# IND83215A register map
Series: Verne; File version: A0
CPU: CM0 r0p1, selectable endian, no MPU, no FPU, 4 interrupt priority bits
Registers are 32-bit, read-write, no defined reset value unless marked. A register's access mark holds for its fields unless they carry their own. Offsets are from the block's base; [hi:lo] are bit positions.

## CRGA — Clock & Reset Generator
Base 0x50000000; register names take the prefix CRGA_
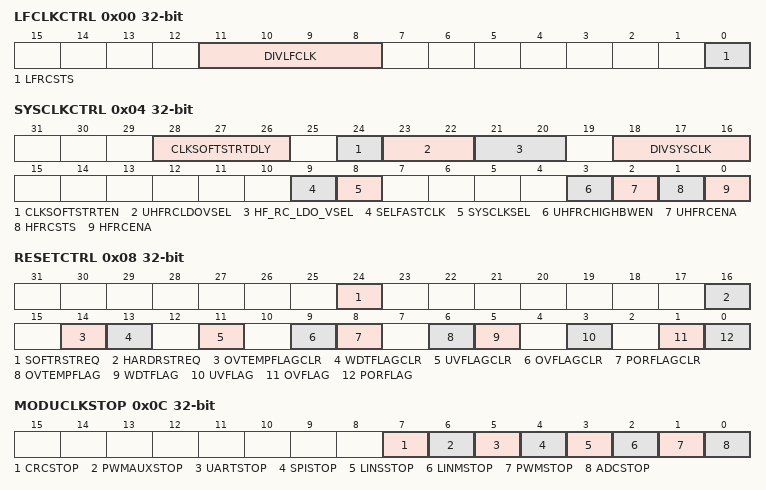
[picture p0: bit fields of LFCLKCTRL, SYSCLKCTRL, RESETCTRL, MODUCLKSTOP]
0x00 LFCLKCTRL — Low frequency clock control
  [11:8] DIVLFCLK — Low Frequency Clock div select. Select the divider ratio on the low Frequency clock when using slow oscillator. Divider ratio is (DIV_LFCLK + 1)
  [0] LFRCSTS ro — Slow oscillator status. Will be high when the Low Frequency oscillator is selected
0x04 SYSCLKCTRL — System clock control
  [28:26] CLKSOFTSTRTDLY — Define the duration of cycles of each divider ratio when soft starting. NOTE: Fast clock selected by SEL_FASTCLK must have been enabled (HF_RC_ENA or UHF_RC_ENA) when change this field. 0x0: 2 divided clock 0x1: 4 divided clock 0x2: 8 divided clock 0x3: 16 divided clock 0x4: 32 divided clock 0x5: 64 divided clock 0x6: 128 divided clock 0x7: 256 divided clock
  [24] CLKSOFTSTRTEN — Enable Clock Soft Starter when change SYSCLKSEL from 0 to 1 for switching to fast clock. When enabled, soft starter will start the clock divider with the maximum divider ratio. And decrease divider ratio by one after staying for predefined number of cycles defined in register field CLKSOFTSTRTDLY. This operation will stop when divider ratio is equal with DIVSYSCLK. NOTE: Fast clock selected by SEL_FASTCLK must have been enabled (HF_RC_ENA or UHF_RC_ENA) when change this field.
  [23:22] UHFRCLDOVSEL — 48MHz RC OSC (UHF Oscillator) LDO output select. 0x0: 1V45 Selected 0x1: 1V50 Selected 0x2: 1V55 Selected 0x3: 1V65 Selected
  [21:20] HF_RC_LDO_VSEL — 16MHz RC OSC (HF Oscillator) LDO output select. 0x0: 1V45 Selected 0x1: 1V50 Selected 0x2: 1V55 Selected 0x3: 1V65 Selected
  [18:16] DIVSYSCLK — Clock div select. Select the divider ratio on the system clock when using fast oscillator. 0x0: No Division. Full Clock speed. 0x1: Div by 2. 0x2: Div by 3. 0x3: Div by 4. 0x4: Div by 5. 0x5: Div by 6. 0x6: Div by 7. 0x7: Div by 8.
  [9] SELFASTCLK — Fast clock select. Used to switch between the ultra high frequency and high frequency oscillator 0x0: high frequency oscillator 0x1: ultra high frequency oscillator
  [8] SYSCLKSEL — System clock select. Used to switch between the fast and slow system clocks NOTE: This bit will be set by hardware after normal POR. 0x0: Slow clock 0x1: Fast clock
  [3] UHFRCHIGHBWEN — Ultra high frequency oscillator comparator high bandwidth enable.
  [2] UHFRCENA — Ultra high frequency oscillator enable. Setting this bit when the Ultra High Frequency oscillator is not running will cause the oscillator to start. This bit is cleared automatically on entering DeepSleep or Hibernate mode. NOTE: UHF oscillator will be stable in 100us after enabled. It is recommended switch to this clock source after it is stable.
  [1] HFRCSTS ro — Fast oscillator status. Will be high when High Frequency oscillator is enabled or fast clock is selected as system clock
  [0] HFRCENA — HF oscillator enable. Setting this bit when the High Frequency oscillator is not running will cause the oscillator to start (the PMU may have already started it). This bit is cleared automatically on entering DeepSleep or Hibernate mode NOTE1: This bit will be set by hardware after normal POR. NOTE2: HF oscillator will be stable in 60us after enabled. It is recommended switch to this clock source after it is stable.
0x08 RESETCTRL — Reset control
  [24] SOFTRSTREQ wo — Soft reset request. Set to trigger a soft reset of chip. Reset all modules in PDLV domain and LINS module Autoclear: includes a synchronous reset signal which clears the register on the cycle following write.
  [16] HARDRSTREQ wo — Hard reset request. Set to trigger a hard reset of chip
  [14] OVTEMPFLAGCLR wo — OVTEMP flag clear. Set to clear the OVTEMP flag
  [13] WDTFLAGCLR wo — WDT flag clear. Set to clear the WDT flag
  [11] UVFLAGCLR wo — UV flag clear. Set to clear the UV flag
  [9] OVFLAGCLR wo — OV flag clear. Set to clear the OV flag
  [8] PORFLAGCLR wo — POR flag clear. Set to clear the POR flag
  [6] OVTEMPFLAG ro — Over Temp Violation flag. Set by the hardware when the over temp condition is detected.
  [5] WDTFLAG ro — Watchdog bark flag. Set by the hardware when the watchdog barks.
  [3] UVFLAG ro — Under Voltage Monitor flag. Set by the hardware when the under voltage monitor.
  [1] OVFLAG ro — Over Voltage Monitor flag. Set by the hardware when the over voltage monitor.
  [0] PORFLAG ro — Power on reset flag. Set by the hardware during power-on reset
0x0C MODUCLKSTOP — Module Clock Stop
  [7] CRCSTOP — CRC Stop. Force to stop the clock of the module, 1: stop is valid; 0: stop is invalid
  [6] PWMAUXSTOP — PWMAUX Stop. Force to stop the clock of the module, 1: stop is valid; 0: stop is invalid
  [5] UARTSTOP — UART Stop. Force to stop the clock of the module, 1: stop is valid; 0: stop is invalid
  [4] SPISTOP — SPI Stop. Force to stop the clock of the module, 1: stop is valid; 0: stop is invalid
  [3] LINSSTOP — LINS Stop. Force to stop the clock of the module, 1: stop is valid; 0: stop is invalid
  [2] LINMSTOP — LINM Stop. Force to stop the clock of the module, 1: stop is valid; 0: stop is invalid
  [1] PWMSTOP — PWM Stop. Force to stop the clock of the module, 1: stop is valid; 0: stop is invalid
  [0] ADCSTOP — ADC Stop. Force to stop the clock of the module, 1: stop is valid; 0: stop is invalid
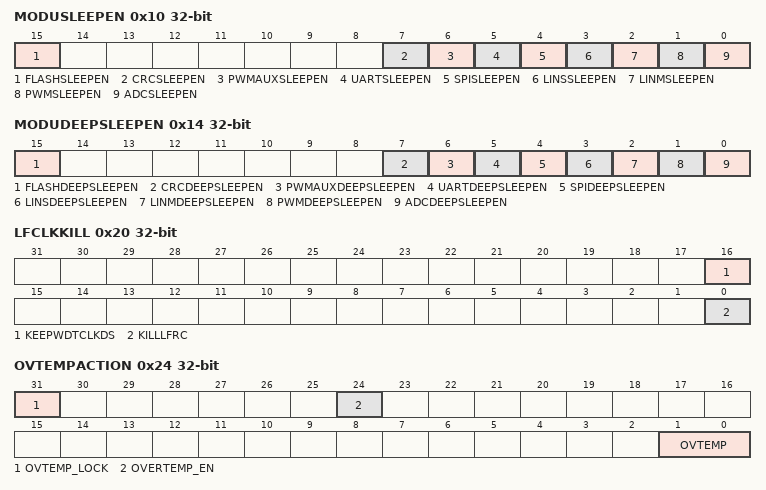
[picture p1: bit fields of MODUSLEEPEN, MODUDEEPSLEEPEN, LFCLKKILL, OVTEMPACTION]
0x10 MODUSLEEPEN — Module Clock Enable in CPU Sleep Mode
  [15] FLASHSLEEPEN — Flash Clock Enable in CPU Sleep Mode. Gate the module clock when CPU has entered sleep, 1: gate is valid; 0: gate is invalid
  [7] CRCSLEEPEN — CRC Clock Enable in CPU Sleep Mode. Gate the module clock when CPU has entered sleep, 1: gate is valid; 0: gate is invalid
  [6] PWMAUXSLEEPEN — PWMAUX Clock Enable in CPU Sleep Mode. Gate the module clock when CPU has entered sleep, 1: gate is valid; 0: gate is invalid
  [5] UARTSLEEPEN — UART Clock Enable in CPU Sleep Mode. Gate the module clock when CPU has entered sleep, 1: gate is valid; 0: gate is invalid
  [4] SPISLEEPEN — SPI Clock Enable in CPU Sleep Mode. Gate the module clock when CPU has entered sleep, 1: gate is valid; 0: gate is invalid
  [3] LINSSLEEPEN — LINS Clock Enable in CPU Sleep Mode. Gate the module clock when CPU has entered sleep, 1: gate is valid; 0: gate is invalid
  [2] LINMSLEEPEN — LINM Clock Enable in CPU Sleep Mode. Gate the module clock when CPU has entered sleep, 1: gate is valid; 0: gate is invalid
  [1] PWMSLEEPEN — PWM Clock Enable in CPU Sleep Mode. Gate the module clock when CPU has entered sleep, 1: gate is valid; 0: gate is invalid
  [0] ADCSLEEPEN — ADC Clock Enable in CPU Sleep Mode. Gate the module clock when CPU has entered sleep, 1: gate is valid; 0: gate is invalid
0x14 MODUDEEPSLEEPEN — Module Clock Enable in CPU Deep Sleep Mode
  [15] FLASHDEEPSLEEPEN — Flash Clock Enable in CPU Deep Sleep Mode. Gate the module clock when CPU has entered deep sleep, 1: gate is valid; 0: gate is invalid
  [7] CRCDEEPSLEEPEN — CRC Clock Enable in CPU Deep Sleep Mode. Gate the module clock when CPU has entered deep sleep, 1: gate is valid; 0: gate is invalid
  [6] PWMAUXDEEPSLEEPEN — PWMAUX Clock Enable in CPU Deep Sleep Mode. Gate the module clock when CPU has entered deep sleep, 1: gate is valid; 0: gate is invalid
  [5] UARTDEEPSLEEPEN — UART Clock Enable in CPU Deep Sleep Mode. Gate the module clock when CPU has entered deep sleep, 1: gate is valid; 0: gate is invalid
  [4] SPIDEEPSLEEPEN — SPI Clock Enable in CPU Deep Sleep Mode. Gate the module clock when CPU has entered deep sleep, 1: gate is valid; 0: gate is invalid
  [3] LINSDEEPSLEEPEN — LINS Clock Enable in CPU Deep Sleep Mode. Gate the module clock when CPU has entered deep sleep, 1: gate is valid; 0: gate is invalid
  [2] LINMDEEPSLEEPEN — LINM Clock Enable in CPU Deep Sleep Mode. Gate the module clock when CPU has entered deep sleep, 1: gate is valid; 0: gate is invalid
  [1] PWMDEEPSLEEPEN — PWM Clock Enable in CPU Deep Sleep Mode. Gate the module clock when CPU has entered deep sleep, 1: gate is valid; 0: gate is invalid
  [0] ADCDEEPSLEEPEN — ADC Clock Enable in CPU Deep Sleep Mode. Gate the module clock when CPU has entered deep sleep, 1: gate is valid; 0: gate is invalid
0x18 MODULERST — Module Reset control
  [7:0] MODULERSTREQ wo — Module Soft reset request. Set to trigger a soft reset of module below. 0x1: ADC Soft reset request 0x2: PWM Soft reset request 0x4: CTT soft reset request 0x8: GTM soft reset request 0x10: SPIM soft reset request 0x20: UART soft reset request 0x40: MATHDIV soft reset request 0x80: CRC soft reset request 0x100: PWM_AUX soft reset request 0x200: LINS soft reset request Autoclear: includes a synchronous reset signal which clears the register on the cycle following write.
0x1C WDTACTION — Watchdog action
  [0] WDTACTION — Watchdog action. Defines the consequences of watchdog bark being detected by the hardware. 0x0: IRQ generated 0x1: Hard reset generated
0x20 LFCLKKILL — Low frequency clock kill
  [16] KEEPWDTCLKDS — Keep WDT clock in Deepsleep. Set to keep WDT clock running in deepsleep mode.
  [0] KILLLFRC — Kill slow RC oscillator. Setting this bit gates the low frequency RC oscillator input
0x24 OVTEMPACTION
  [31] OVTEMP_LOCK — Set Only bit. Set this bit to lock OVTEMP related bits.
  [24] OVERTEMP_EN — OverTemp Monitor Enable bit.
  [1:0] OVTEMP — Over Temperature action. Defines the consequences of over temp condition detected by the hardware. 0x2: No action 0x1: IRQ generated 0x0: Hard reset generated
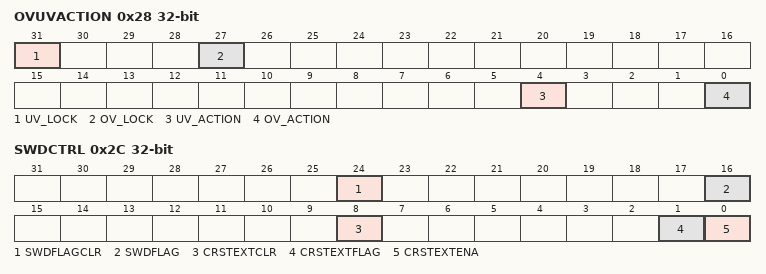
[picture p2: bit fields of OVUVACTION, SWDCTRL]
0x28 OVUVACTION
  [31] UV_LOCK — Set Only bit. Set this bit to lock UV_ACTION related bits.
  [27] OV_LOCK — Set Only bit. Set this bit to lock OV_ACTION related bits.
  [4] UV_ACTION — Under Voltage action. Defines the consequences of under voltage condition detected by the hardware. 0x1: No action 0x0: Hard reset generated
  [0] OV_ACTION — Over Voltage action. Defines the consequences of over voltage condition detected by the hardware. 0x1: No action 0x0: Hard reset generated
0x2C SWDCTRL — Swd debug control
  [24] SWDFLAGCLR wo — SWD Wakeup flag clear. Set to clear the SWD Wakeup flag
  [16] SWDFLAG ro — SWD wakeup flag. Set by the hardware when chip is awakened by SWD from deepsleep mode and clear through SWDFLAGCLR.
  [8] CRSTEXTCLR wo — M0 core extend reset clear. clear M0 core extend reset
  [1] CRSTEXTFLAG ro — M0 core extend reset flag. Set by the hardware when: 1) both CRSTEXTENA and SWDFLAG are high; or 2) SWCLK is high when power up or exit from hibernate or exit from deepsleep. Clear through CRSTEXTCLR. CPU core will hold in reset state until this bit is cleared.
  [0] CRSTEXTENA — M0 core extend reset enable. enable M0 core extented reset when chip is awakened by SWD from deepsleep mode
